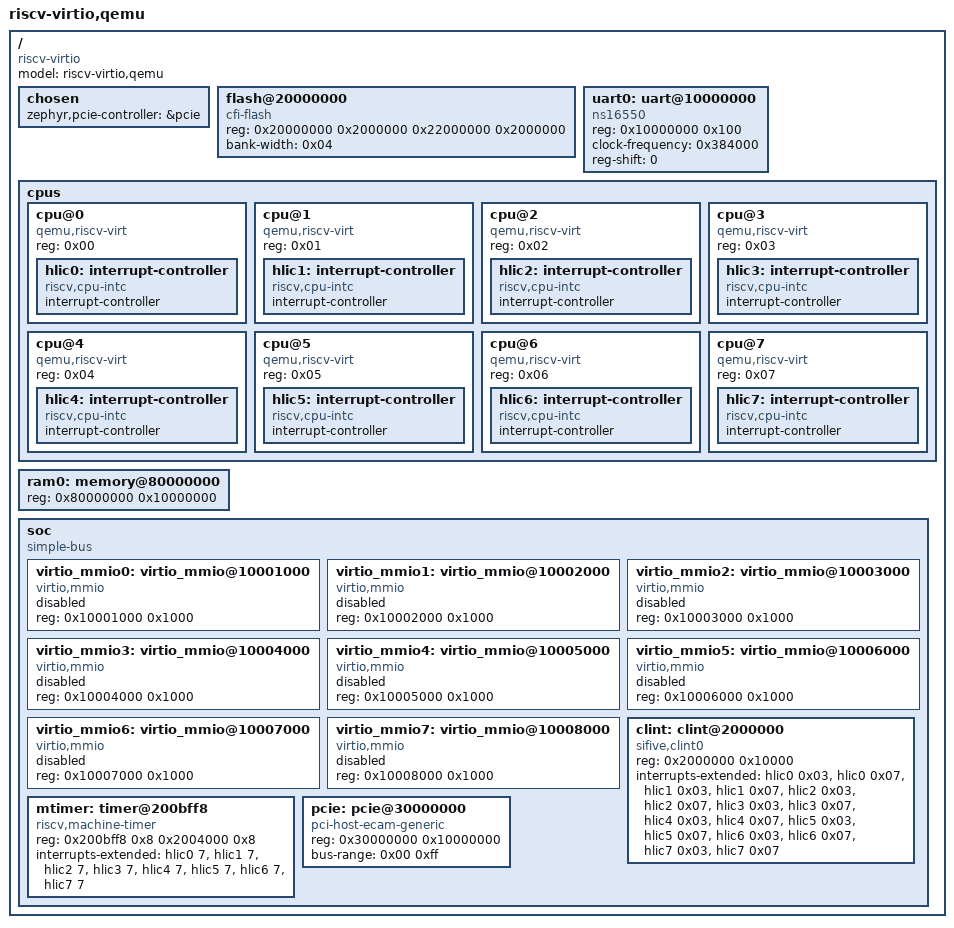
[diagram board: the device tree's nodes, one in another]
/*
 * Copyright (c) 2020 Cobham Gaisler AB
 *
 * SPDX-License-Identifier: Apache-2.0
 */

/*
 * This file is based on:
 *   qemu-system-riscv32 -machine virt,dumpdtb=virt.dtb -smp 8 -m 256
 *   dtc virt.dtb > virt.dtsi
 */

/dts-v1/;

/ {
	compatible = "riscv-virtio";
	#address-cells = <0x01>;
	#size-cells = <0x01>;
	model = "riscv-virtio,qemu";

	chosen {
		zephyr,pcie-controller = &pcie;
	};

	flash@20000000 {
		compatible = "cfi-flash";
		reg = <0x20000000 0x2000000 0x22000000 0x2000000>;
		bank-width = <0x04>;
	};

	uart0: uart@10000000 {
		compatible = "ns16550";
		reg = <0x10000000 0x100>;
		clock-frequency = <0x384000>;
		reg-shift = <0>;
	};

	cpus {
		#address-cells = <0x01>;
		#size-cells = <0x00>;

		cpu@0 {
			compatible = "qemu,riscv-virt", "riscv";
			reg = <0x00>;
			device_type = "cpu";
			status = "okay";

			hlic0: interrupt-controller {
				compatible = "riscv,cpu-intc";
				#address-cells = <0>;
				#interrupt-cells = <0x01>;
				interrupt-controller;
			};
		};

		cpu@1 {
			compatible = "qemu,riscv-virt", "riscv";
			reg = <0x01>;
			device_type = "cpu";
			status = "okay";

			hlic1: interrupt-controller {
				compatible = "riscv,cpu-intc";
				#address-cells = <0>;
				#interrupt-cells = <0x01>;
				interrupt-controller;
			};
		};

		cpu@2 {
			compatible = "qemu,riscv-virt", "riscv";
			reg = <0x02>;
			device_type = "cpu";
			status = "okay";

			hlic2: interrupt-controller {
				compatible = "riscv,cpu-intc";
				#address-cells = <0>;
				#interrupt-cells = <0x01>;
				interrupt-controller;
			};
		};

		cpu@3 {
			compatible = "qemu,riscv-virt", "riscv";
			reg = <0x03>;
			device_type = "cpu";
			status = "okay";

			hlic3: interrupt-controller {
				compatible = "riscv,cpu-intc";
				#address-cells = <0>;
				#interrupt-cells = <0x01>;
				interrupt-controller;
			};
		};

		cpu@4 {
			compatible = "qemu,riscv-virt", "riscv";
			reg = <0x04>;
			device_type = "cpu";
			status = "okay";

			hlic4: interrupt-controller {
				compatible = "riscv,cpu-intc";
				#address-cells = <0>;
				#interrupt-cells = <0x01>;
				interrupt-controller;
			};
		};

		cpu@5 {
			compatible = "qemu,riscv-virt", "riscv";
			reg = <0x05>;
			device_type = "cpu";
			status = "okay";

			hlic5: interrupt-controller {
				compatible = "riscv,cpu-intc";
				#address-cells = <0>;
				#interrupt-cells = <0x01>;
				interrupt-controller;
			};
		};

		cpu@6 {
			compatible = "qemu,riscv-virt", "riscv";
			reg = <0x06>;
			device_type = "cpu";
			status = "okay";

			hlic6: interrupt-controller {
				compatible = "riscv,cpu-intc";
				#address-cells = <0>;
				#interrupt-cells = <0x01>;
				interrupt-controller;
			};
		};

		cpu@7 {
			compatible = "qemu,riscv-virt", "riscv";
			reg = <0x07>;
			device_type = "cpu";
			status = "okay";

			hlic7: interrupt-controller {
				compatible = "riscv,cpu-intc";
				#address-cells = <0>;
				#interrupt-cells = <0x01>;
				interrupt-controller;
			};
		};
	};

	ram0: memory@80000000 {
		reg = <0x80000000 0x10000000>;
		device_type = "memory";
	};

	soc {
		compatible = "simple-bus";
		ranges;
		#address-cells = <0x01>;
		#size-cells = <0x01>;

		virtio_mmio0: virtio_mmio@10001000 {
			compatible = "virtio,mmio";
			reg = <0x10001000 0x1000>;
			status = "disabled";
		};

		virtio_mmio1: virtio_mmio@10002000 {
			compatible = "virtio,mmio";
			reg = <0x10002000 0x1000>;
			status = "disabled";
		};

		virtio_mmio2: virtio_mmio@10003000 {
			compatible = "virtio,mmio";
			reg = <0x10003000 0x1000>;
			status = "disabled";
		};

		virtio_mmio3: virtio_mmio@10004000 {
			compatible = "virtio,mmio";
			reg = <0x10004000 0x1000>;
			status = "disabled";
		};

		virtio_mmio4: virtio_mmio@10005000 {
			compatible = "virtio,mmio";
			reg = <0x10005000 0x1000>;
			status = "disabled";
		};

		virtio_mmio5: virtio_mmio@10006000 {
			compatible = "virtio,mmio";
			reg = <0x10006000 0x1000>;
			status = "disabled";
		};

		virtio_mmio6: virtio_mmio@10007000 {
			compatible = "virtio,mmio";
			reg = <0x10007000 0x1000>;
			status = "disabled";
		};

		virtio_mmio7: virtio_mmio@10008000 {
			compatible = "virtio,mmio";
			reg = <0x10008000 0x1000>;
			status = "disabled";
		};

		clint: clint@2000000 {
			compatible = "sifive,clint0";
			reg = <0x2000000 0x10000>;
			interrupts-extended = <&hlic0 0x03 &hlic0 0x07
					       &hlic1 0x03 &hlic1 0x07
					       &hlic2 0x03 &hlic2 0x07
					       &hlic3 0x03 &hlic3 0x07
					       &hlic4 0x03 &hlic4 0x07
					       &hlic5 0x03 &hlic5 0x07
					       &hlic6 0x03 &hlic6 0x07
					       &hlic7 0x03 &hlic7 0x07>;
		};

		mtimer: timer@200bff8 {
			compatible = "riscv,machine-timer";
			reg = <0x200bff8 0x8 0x2004000 0x8>;
			interrupts-extended = <&hlic0 7
					       &hlic1 7
					       &hlic2 7
					       &hlic3 7
					       &hlic4 7
					       &hlic5 7
					       &hlic6 7
					       &hlic7 7>;
			reg-names = "mtime", "mtimecmp";
		};

		pcie: pcie@30000000 {
			compatible = "pci-host-ecam-generic";
			reg = <0x30000000 0x10000000>;
			ranges = <0x1000000 0x00 0x00 0x3000000 0x00 0x10000
				  0x2000000 0x00 0x40000000 0x40000000 0x00 0x40000000>;
			device_type = "pci";
			#size-cells = <0x02>;
			#address-cells = <0x03>;
			#interrupt-cells = <0x01>;
			bus-range = <0x00 0xff>;
		};
	};
};
